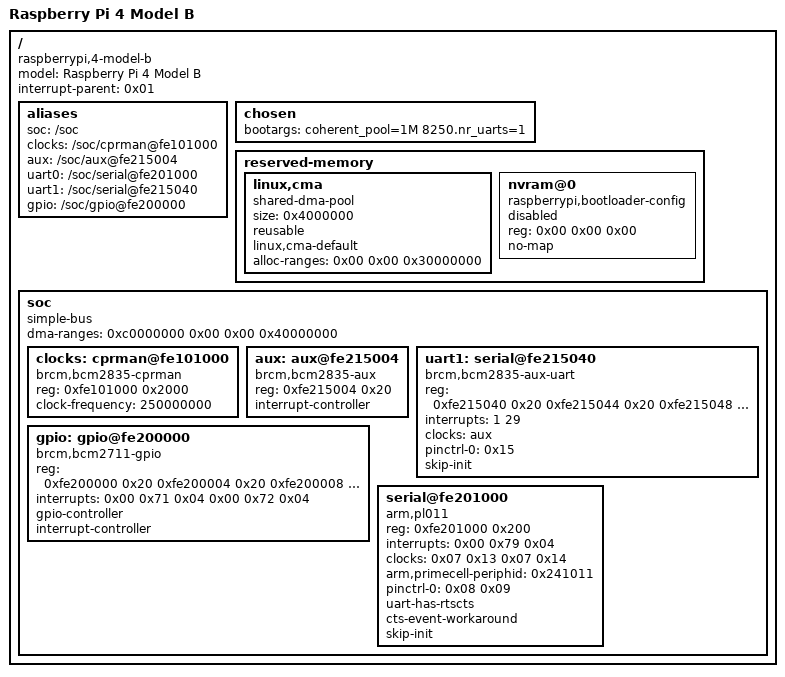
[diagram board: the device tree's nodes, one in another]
/dts-v1/;

/memreserve/	0x0000000000000000 0x0000000000001000;
/ {
	compatible = "raspberrypi,4-model-b\0brcm,bcm2711";
	model = "Raspberry Pi 4 Model B";
	#address-cells = <0x02>;
	#size-cells = <0x01>;
	interrupt-parent = <0x01>;

	aliases {
		soc = "/soc";
		clocks = "/soc/cprman@fe101000";
		aux = "/soc/aux@fe215004";
		uart0 = "/soc/serial@fe201000";
		uart1 = "/soc/serial@fe215040";
		gpio = "/soc/gpio@fe200000";
	};

	chosen {
		bootargs = "coherent_pool=1M 8250.nr_uarts=1";
	};

	reserved-memory {
		#address-cells = <0x02>;
		#size-cells = <0x01>;
		ranges;
		phandle = <0x41>;

		linux,cma {
			compatible = "shared-dma-pool";
			size = <0x4000000>;
			reusable;
			linux,cma-default;
			alloc-ranges = <0x00 0x00 0x30000000>;
			phandle = <0x42>;
		};

		nvram@0 {
			compatible = "raspberrypi,bootloader-config\0nvmem-rmem";
			#address-cells = <0x01>;
			#size-cells = <0x01>;
			reg = <0x00 0x00 0x00>;
			no-map;
			status = "disabled";
			phandle = <0x43>;
		};
	};


	soc {
		compatible = "simple-bus";
		#address-cells = <0x01>;
		#size-cells = <0x01>;
		dma-ranges = <0xc0000000 0x00 0x00 0x40000000>;
		phandle = <0x45>;
		
		clocks: cprman@fe101000 {
			compatible = "brcm,bcm2835-cprman";
			#clock-cells = <1>;
			reg = <0xfe101000 0x2000>;
			clock-frequency = "250000000";
		};

		aux: aux@fe215004 {
			compatible = "brcm,bcm2835-aux";
			reg = <0xfe215004 0x20>;
			#clock-cells = <1>;
			interrupt-controller;
			#interrupt-cells = <1>;
		};


		uart1: serial@fe215040 {
			compatible = "brcm,bcm2835-aux-uart"; // indica el controlador o driver compatible con el dispositivo, en este caso del uart.
			reg = <0xfe215040 0x20 0xfe215044 0x20 
				   0xfe215048 0x20 0xfe21504c 0x20 
				   0xfe215050 0x20 0xfe215054 0x20
				   0xfe215058 0x20 0xfe21505c 0x20
				   0xfe215060 0x20 0xfe215064 0x20
				   0xfe215068 0x20>; // ver si tengo que cambiar el registro
			interrupts = <1 29>; 
			
			clocks = <&aux>;

			status = "okay";
			pinctrl-names = "default";
			pinctrl-0 = <0x15>;
			skip-init;
			phandle = <0x31>;

		};

		gpio: gpio@fe200000 {
			compatible = "brcm,bcm2711-gpio";
			reg = <0xfe200000 0x20 0xfe200004 0x20 
				   0xfe200008 0x20 0xfe20000c 0x20
				   0xfe200010 0x20 0xfe200014 0x20
				   0xfe20001c 0x20 0xfe200020 0x20
				   0xfe200028 0x20 0xfe200034 0x20
				   0xfe200038 0x20 0xfe200040 0x20
				   0xfe200044 0x20 0xfe200064 0x20
				   0xfe200068 0x20 0xfe200094 0x20
				   0xfe200098 0x20 0xfe20009c 0x20>;
			
			interrupts = <0x00 0x71 0x04 0x00 0x72 0x04>;
			gpio-controller;
			#gpio-cells = <0x02>;
			interrupt-controller;
			#interrupt-cells = <0x02>;
			pinctrl-names = "default";
			// gpio-line-names = "ID_SDA\0ID_SCL\0SDA1\0SCL1\0GPIO_GCLK\0GPIO5\0GPIO6\0SPI_CE1_N\0SPI_CE0_N\0SPI_MISO\0SPI_MOSI\0SPI_SCLK\0GPIO12\0GPIO13\0TXD1\0RXD1\0GPIO16\0GPIO17\0GPIO18\0GPIO19\0GPIO20\0GPIO21\0GPIO22\0GPIO23\0GPIO24\0GPIO25\0GPIO26\0GPIO27\0RGMII_MDIO\0RGMIO_MDC\0CTS0\0RTS0\0TXD0\0RXD0\0SD1_CLK\0SD1_CMD\0SD1_DATA0\0SD1_DATA1\0SD1_DATA2\0SD1_DATA3\0PWM0_MISO\0PWM1_MOSI\0STATUS_LED_G_CLK\0SPIFLASH_CE_N\0SDA0\0SCL0\0RGMII_RXCLK\0RGMII_RXCTL\0RGMII_RXD0\0RGMII_RXD1\0RGMII_RXD2\0RGMII_RXD3\0RGMII_TXCLK\0RGMII_TXCTL\0RGMII_TXD0\0RGMII_TXD1\0RGMII_TXD2\0RGMII_TXD3";
			phandle = <0x0f>;

		};


		serial@fe201000 {
			compatible = "arm,pl011\0arm,primecell";
			reg = <0xfe201000 0x200>;
			interrupts = <0x00 0x79 0x04>;
			clocks = <0x07 0x13 0x07 0x14>;
			clock-names = "uartclk\0apb_pclk";
			arm,primecell-periphid = <0x241011>;
			pinctrl-names = "default";
			pinctrl-0 = <0x08 0x09>;
			uart-has-rtscts;
			status = "okay";
			cts-event-workaround;
			skip-init;
			phandle = <0x30>;

		};

	};


	// VER SI AÑADIR A OVERRIDES Y A SYMBOLS

	__overrides__ {
		uart1 = "\0\0\01status";
	};


	__symbols__ {
		rmem = "/reserved-memory";
		soc = "/soc";
		uart1 = "/soc/serial@fe215000";
	};
};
